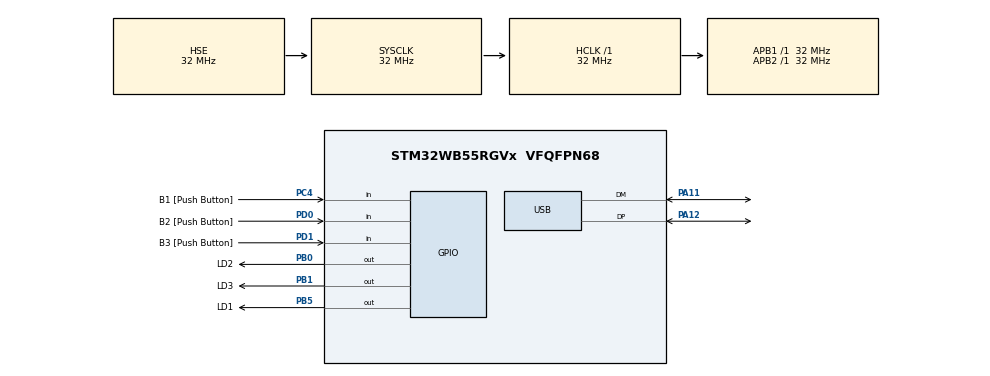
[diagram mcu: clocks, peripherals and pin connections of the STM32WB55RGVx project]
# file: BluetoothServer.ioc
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Mcu.Family=STM32WB
Mcu.Name=STM32WB55RGVx
Mcu.Package=VFQFPN68
NVIC.HSEM_IRQn=true\:0\:0\:false\:false\:true\:false\:true\:true
NVIC.PriorityGroup=NVIC_PRIORITYGROUP_4
NVIC.USB_LP_IRQn=true\:0\:0\:false\:false\:true\:false\:true\:true
OSC_IN.Mode=HSE-External-Oscillator
OSC_IN.Signal=RCC_OSC_IN
OSC_OUT.Mode=HSE-External-Oscillator
OSC_OUT.Signal=RCC_OSC_OUT
PA11.Mode=Device
PA11.Signal=USB_DM
PA12.Mode=Device
PA12.Signal=USB_DP
PA13.GPIO_Label=JTMS
PA13.Mode=Trace_Asynchronous_SW
PA13.Signal=SYS_JTMS-SWDIO
PA14.GPIO_Label=JTCK
PA14.Mode=Trace_Asynchronous_SW
PA14.Signal=SYS_JTCK-SWCLK
PB0.GPIO_Label=LD2
PB0.Signal=GPIO_Output
PB1.GPIO_Label=LD3
PB1.Signal=GPIO_Output
PB3.GPIO_Label=JTDO
PB3.Mode=Trace_Asynchronous_SW
PB3.Signal=SYS_JTDO-SWO
PB5.GPIO_Label=LD1
PB5.Signal=GPIO_Output
PC13.Mode=SYS_WakeUp1
PC13.Signal=SYS_WKUP2
PC14-OSC32_IN.Mode=LSE-External-Oscillator
PC14-OSC32_IN.Signal=RCC_OSC32_IN
PC15-OSC32_OUT.Mode=LSE-External-Oscillator
PC15-OSC32_OUT.Signal=RCC_OSC32_OUT
PC4.GPIO_Label=B1 [Push Button]
PC4.Signal=GPIO_Input
PD0.GPIO_Label=B2 [Push Button]
PD0.Signal=GPIO_Input
PD1.GPIO_Label=B3 [Push Button]
PD1.Signal=GPIO_Input
ProjectManager.HeapSize=0x200
ProjectManager.StackSize=0x400
ProjectManager.TargetToolchain=STM32CubeIDE
RCC.ADCFreq_Value=48000000
RCC.AHBFreq_Value=32000000
RCC.APB1Freq_Value=32000000
RCC.APB1TimFreq_Value=32000000
RCC.APB2Freq_Value=32000000
RCC.APB2TimFreq_Value=32000000
RCC.APB3Freq_Value=16000000
RCC.CK48CLockSelection=RCC_USBCLKSOURCE_HSI48
RCC.CortexFreq_Value=32000000
RCC.HCLKFreq_Value=32000000
RCC.HSE_VALUE=32000000
RCC.HSI48_VALUE=48000000
RCC.HSI_VALUE=16000000
RCC.PLLN=32
RCC.PLLSAI1N=24
RCC.RFWKPClockSelection=RCC_RFWKPCLKSOURCE_LSE
RCC.RTCClockSelection=RCC_RTCCLKSOURCE_LSE
RCC.SMPSCLockSelectionVirtual=RCC_SMPSCLKSOURCE_HSI
RCC.SMPSCLockSelectionVirtualVirtual=RCC_SMPSCLKSOURCE_HSI
RCC.SMPSDivider=1
RCC.SYSCLKFreq_VALUE=32000000
RCC.SYSCLKSource=RCC_SYSCLKSOURCE_HSE
RCC.USBFreq_Value=48000000
RCC.VCOOutputFreq_Value=128000000
RF1.Mode=RF1_Activate
RF1.Signal=RF_RF1
USB_DEVICE.CLASS_NAME_FS=CDC
USB_DEVICE.VirtualMode=Cdc
USB_DEVICE.VirtualModeFS=Cdc_FS
VP_HSEM_VS_HSEM.Mode=HSEM_Activate
VP_RTC_VS_RTC_Activate.Mode=RTC_Enabled
VP_SEQUENCER_VS_SEQUENCER.Mode=SEQUENCER_Enabled
VP_STM32_WPAN_VS_BLE_HOST.Mode=STM32_WPAN_Enabled
VP_TINY_LPM_VS_TINY_LPM.Mode=TINY_LPM_Enabled
VP_USB_DEVICE_VS_USB_DEVICE_CDC_FS.Mode=CDC_FS
board=NUCLEO-WB55RG

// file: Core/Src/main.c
/* USER CODE BEGIN Header */
/**
  ******************************************************************************
  * @file           : main.c
  * @brief          : Main program body
  ******************************************************************************
  * @attention
  *
  * Copyright (c) 2022 STMicroelectronics.
  * All rights reserved.
  *
  * This software is licensed under terms that can be found in the LICENSE file
  * in the root directory of this software component.
  * If no LICENSE file comes with this software, it is provided AS-IS.
  *
  ******************************************************************************
  */
/* USER CODE END Header */
#include "main.h"
#include "usb_device.h"

/* USER CODE BEGIN Includes */
#include "stm32_seq.h"
#include "usbd_cdc_if.h"
/* USER CODE END Includes */

RTC_HandleTypeDef hrtc;

void SystemClock_Config(void);
void PeriphCommonClock_Config(void);
static void MX_GPIO_Init(void);
static void MX_RF_Init(void);
static void MX_RTC_Init(void);
/* USER CODE BEGIN PFP */
int _write (int file, char *ptr, int len) {
	CDC_Transmit_FS ((uint8_t *)ptr,len);
	return len;
}
/* USER CODE END PFP */
uint8_t rxUart[2]={0,0};

int main(void)
{

  /* MCU Configuration--------------------------------------------------------*/

  /* Reset of all peripherals, Initializes the Flash interface and the Systick. */
  HAL_Init();
  /* Config code for STM32_WPAN (HSE Tuning must be done before system clock configuration) */
  MX_APPE_Config();

  /* Configure the system clock */
  SystemClock_Config();

/* Configure the peripherals common clocks */
  PeriphCommonClock_Config();

  /* Initialize all configured peripherals */
  MX_GPIO_Init();
  MX_RF_Init();
  MX_RTC_Init();
  MX_USB_Device_Init();

  /* Init code for STM32_WPAN */
  //MX_APPE_Init();

  /* Infinite loop */
  while (1)
  {
    //MX_APPE_Process();
    UTIL_SEQ_Run (UTIL_SEQ_DEFAULT);

  }
}

void SystemClock_Config(void)
{
  RCC_OscInitTypeDef RCC_OscInitStruct = {0};
  RCC_ClkInitTypeDef RCC_ClkInitStruct = {0};

  /** Configure LSE Drive Capability
  */
  HAL_PWR_EnableBkUpAccess();
  __HAL_RCC_LSEDRIVE_CONFIG(RCC_LSEDRIVE_LOW);

  /** Configure the main internal regulator output voltage
  */
  __HAL_PWR_VOLTAGESCALING_CONFIG(PWR_REGULATOR_VOLTAGE_SCALE1);

  /** Initializes the RCC Oscillators according to the specified parameters
  * in the RCC_OscInitTypeDef structure.
  */
  RCC_OscInitStruct.OscillatorType = RCC_OSCILLATORTYPE_HSI48|RCC_OSCILLATORTYPE_HSI
                              |RCC_OSCILLATORTYPE_HSE|RCC_OSCILLATORTYPE_LSE;
  RCC_OscInitStruct.HSEState = RCC_HSE_ON;
  RCC_OscInitStruct.LSEState = RCC_LSE_ON;
  RCC_OscInitStruct.HSIState = RCC_HSI_ON;
  RCC_OscInitStruct.HSI48State = RCC_HSI48_ON;
  RCC_OscInitStruct.HSICalibrationValue = RCC_HSICALIBRATION_DEFAULT;
  RCC_OscInitStruct.PLL.PLLState = RCC_PLL_NONE;
  if (HAL_RCC_OscConfig(&RCC_OscInitStruct) != HAL_OK)
  {
    Error_Handler();
  }

  /** Configure the SYSCLKSource, HCLK, PCLK1 and PCLK2 clocks dividers
  */
  RCC_ClkInitStruct.ClockType = RCC_CLOCKTYPE_HCLK4|RCC_CLOCKTYPE_HCLK2
                              |RCC_CLOCKTYPE_HCLK|RCC_CLOCKTYPE_SYSCLK
                              |RCC_CLOCKTYPE_PCLK1|RCC_CLOCKTYPE_PCLK2;
  RCC_ClkInitStruct.SYSCLKSource = RCC_SYSCLKSOURCE_HSE;
  RCC_ClkInitStruct.AHBCLKDivider = RCC_SYSCLK_DIV1;
  RCC_ClkInitStruct.APB1CLKDivider = RCC_HCLK_DIV1;
  RCC_ClkInitStruct.APB2CLKDivider = RCC_HCLK_DIV1;
  RCC_ClkInitStruct.AHBCLK2Divider = RCC_SYSCLK_DIV1;
  RCC_ClkInitStruct.AHBCLK4Divider = RCC_SYSCLK_DIV1;

  if (HAL_RCC_ClockConfig(&RCC_ClkInitStruct, FLASH_LATENCY_1) != HAL_OK)
  {
    Error_Handler();
  }
}

void PeriphCommonClock_Config(void)
{
  RCC_PeriphCLKInitTypeDef PeriphClkInitStruct = {0};

  /** Initializes the peripherals clock
  */
  PeriphClkInitStruct.PeriphClockSelection = RCC_PERIPHCLK_SMPS|RCC_PERIPHCLK_RFWAKEUP;
  PeriphClkInitStruct.RFWakeUpClockSelection = RCC_RFWKPCLKSOURCE_LSE;
  PeriphClkInitStruct.SmpsClockSelection = RCC_SMPSCLKSOURCE_HSI;
  PeriphClkInitStruct.SmpsDivSelection = RCC_SMPSCLKDIV_RANGE0;

  if (HAL_RCCEx_PeriphCLKConfig(&PeriphClkInitStruct) != HAL_OK)
  {
    Error_Handler();
  }
}

static void MX_RF_Init(void)
{

}

static void MX_RTC_Init(void)
{

  /** Initialize RTC Only
  */
  hrtc.Instance = RTC;
  hrtc.Init.HourFormat = RTC_HOURFORMAT_24;
  hrtc.Init.AsynchPrediv = CFG_RTC_ASYNCH_PRESCALER;
  hrtc.Init.SynchPrediv = CFG_RTC_SYNCH_PRESCALER;
  hrtc.Init.OutPut = RTC_OUTPUT_DISABLE;
  hrtc.Init.OutPutPolarity = RTC_OUTPUT_POLARITY_HIGH;
  hrtc.Init.OutPutType = RTC_OUTPUT_TYPE_OPENDRAIN;
  hrtc.Init.OutPutRemap = RTC_OUTPUT_REMAP_NONE;
  if (HAL_RTC_Init(&hrtc) != HAL_OK)
  {
    Error_Handler();
  }

}

static void MX_GPIO_Init(void)
{
  GPIO_InitTypeDef GPIO_InitStruct = {0};

  /* GPIO Ports Clock Enable */
  __HAL_RCC_GPIOC_CLK_ENABLE();
  __HAL_RCC_GPIOB_CLK_ENABLE();
  __HAL_RCC_GPIOA_CLK_ENABLE();
  __HAL_RCC_GPIOD_CLK_ENABLE();

  /*Configure GPIO pin Output Level */
  HAL_GPIO_WritePin(GPIOB, LD2_Pin|LD3_Pin|LD1_Pin, GPIO_PIN_RESET);

  /*Configure GPIO pin : B1_Pin */
  GPIO_InitStruct.Pin = B1_Pin;
  GPIO_InitStruct.Mode = GPIO_MODE_INPUT;
  GPIO_InitStruct.Pull = GPIO_NOPULL;
  HAL_GPIO_Init(B1_GPIO_Port, &GPIO_InitStruct);

  /*Configure GPIO pins : LD2_Pin LD3_Pin LD1_Pin */
  GPIO_InitStruct.Pin = LD2_Pin|LD3_Pin|LD1_Pin;
  GPIO_InitStruct.Mode = GPIO_MODE_OUTPUT_PP;
  GPIO_InitStruct.Pull = GPIO_NOPULL;
  GPIO_InitStruct.Speed = GPIO_SPEED_FREQ_LOW;
  HAL_GPIO_Init(GPIOB, &GPIO_InitStruct);

  /*Configure GPIO pins : B2_Pin B3_Pin */
  GPIO_InitStruct.Pin = B2_Pin|B3_Pin;
  GPIO_InitStruct.Mode = GPIO_MODE_INPUT;
  GPIO_InitStruct.Pull = GPIO_NOPULL;
  HAL_GPIO_Init(GPIOD, &GPIO_InitStruct);

}

void Error_Handler(void)
{
  __disable_irq();
  while (1)
  {
  }
}
